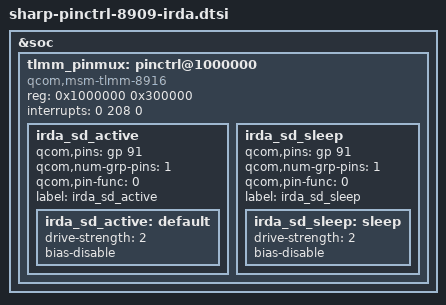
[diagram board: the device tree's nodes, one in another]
/*
 * Copyright (C) 2015 SHARP CORPORATION All rights reserved.
 *
 * This software is licensed under the terms of the GNU General Public
 * License version 2, as published by the Free Software Foundation, and
 * may be copied, distributed, and modified under those terms.
 *
 * This program is distributed in the hope that it will be useful,
 * but WITHOUT ANY WARRANTY; without even the implied warranty of
 * MERCHANTABILITY or FITNESS FOR A PARTICULAR PURPOSE.  See the
 * GNU General Public License for more details.
 *
 */

&soc {
	tlmm_pinmux: pinctrl@1000000 {
		compatible = "qcom,msm-tlmm-8916";
		reg = <0x1000000 0x300000>;
		interrupts = <0 208 0>;

		/*****************************************/
		/*  pinctrl customize setting            */
		/*  IrDA                                 */
		/*****************************************/

		irda_sd_active {
			qcom,pins = <&gp 91>;
			qcom,num-grp-pins = <1>;
			qcom,pin-func = <0>;
		        label = "irda_sd_active";
			irda_sd_active: default {
				drive-strength = <2>;
				bias-disable;
			};
		};

		irda_sd_sleep {
			qcom,pins = <&gp 91>;
			qcom,num-grp-pins = <1>;
			qcom,pin-func = <0>;
		        label = "irda_sd_sleep";
			irda_sd_sleep: sleep {
				drive-strength = <2>;
				bias-disable;
			};
		};

	};

};
